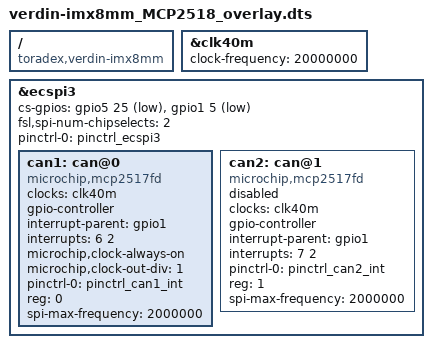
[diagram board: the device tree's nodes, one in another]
// SPDX-License-Identifier: Apache-2
/*
 * Copyright 2020-2021 Opentrons
 */

// Verdin SPI CAN controller mcp2517fd.

/dts-v1/;
/plugin/;

/ {
	compatible = "toradex,verdin-imx8mm";
};
// http://git.toradex.com/cgit/linux-toradex.git/commit/?id=226073276f6be24718d364b0cfd12019c07cab14
&clk40m {
    clock-frequency = <20000000>;
};

/* Verdin CAN_1 and CAN_2 (on-module) */
&ecspi3 {
	#address-cells = <1>;
	#size-cells = <0>;
	cs-gpios = <&gpio5 25 1>,
		   <&gpio1 5 1>;
	/* This property is required, even if marked as obsolete in the doku */
	fsl,spi-num-chipselects = <2>;
	pinctrl-names = "default";
	pinctrl-0 = <&pinctrl_ecspi3>;
	status = "okay";

	can1: can@0 {
		compatible = "microchip,mcp2517fd";
		clocks = <&clk40m>;
		gpio-controller;
		interrupt-parent = <&gpio1>;
		interrupts = <6 2>;
		microchip,clock-always-on;
		microchip,clock-out-div = <1>;
		pinctrl-names = "default";
		pinctrl-0 = <&pinctrl_can1_int>;
		reg = <0>;
		spi-max-frequency = <2000000>;
	};

	can2: can@1 {
		compatible = "microchip,mcp2517fd";
		clocks = <&clk40m>;
		gpio-controller;
		interrupt-parent = <&gpio1>;
		interrupts = <7 2>;
		pinctrl-names = "default";
		pinctrl-0 = <&pinctrl_can2_int>;
		reg = <1>;
		spi-max-frequency = <2000000>;
		/* not assembled */
		status = "disabled";
	};
};
